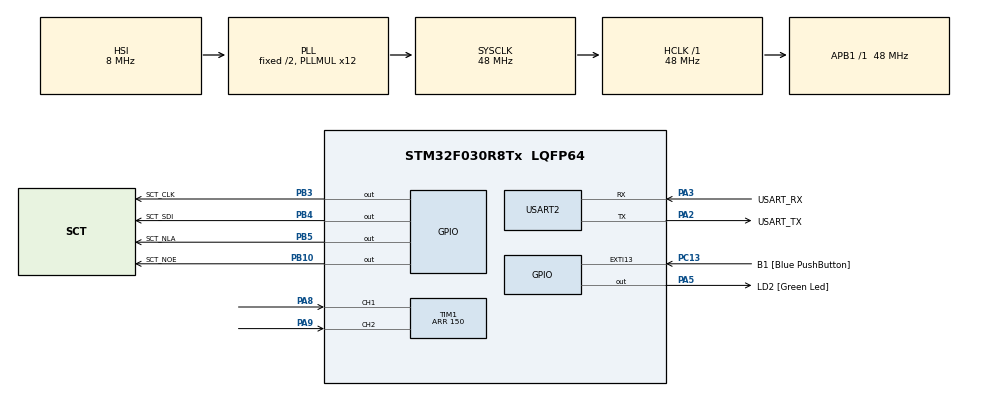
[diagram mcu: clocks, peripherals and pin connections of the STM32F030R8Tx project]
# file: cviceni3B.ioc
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Mcu.Family=STM32F0
Mcu.Name=STM32F030R8Tx
Mcu.Package=LQFP64
PA13.GPIO_Label=TMS
PA13.Mode=Serial_Wire
PA13.Signal=SYS_SWDIO
PA14.GPIO_Label=TCK
PA14.Mode=Serial_Wire
PA14.Signal=SYS_SWCLK
PA2.GPIO_Label=USART_TX
PA2.GPIO_Mode=GPIO_MODE_AF_PP
PA2.GPIO_PuPd=GPIO_NOPULL
PA2.GPIO_Speed=GPIO_SPEED_FREQ_LOW
PA2.Mode=Asynchronous
PA2.Signal=USART2_TX
PA3.GPIO_Label=USART_RX
PA3.GPIO_Mode=GPIO_MODE_AF_PP
PA3.GPIO_PuPd=GPIO_NOPULL
PA3.GPIO_Speed=GPIO_SPEED_FREQ_LOW
PA3.Mode=Asynchronous
PA3.Signal=USART2_RX
PA5.GPIO_Label=LD2 [Green Led]
PA5.GPIO_Mode=GPIO_MODE_OUTPUT_PP
PA5.GPIO_PuPd=GPIO_NOPULL
PA5.GPIO_Speed=GPIO_SPEED_FREQ_LOW
PA5.Signal=GPIO_Output
PA8.Signal=S_TIM1_CH1
PA9.Signal=S_TIM1_CH2
PB10.GPIO_Label=SCT_NOE
PB10.Signal=GPIO_Output
PB3.GPIO_Label=SCT_CLK
PB3.Signal=GPIO_Output
PB4.GPIO_Label=SCT_SDI
PB4.Signal=GPIO_Output
PB5.GPIO_Label=SCT_NLA
PB5.Signal=GPIO_Output
PC13.GPIO_Label=B1 [Blue PushButton]
PC13.GPIO_ModeDefaultEXTI=GPIO_MODE_IT_FALLING
PC13.Signal=GPXTI13
PC14-OSC32_IN.Mode=LSE-External-Oscillator
PC14-OSC32_IN.Signal=RCC_OSC32_IN
PC15-OSC32_OUT.Mode=LSE-External-Oscillator
PC15-OSC32_OUT.Signal=RCC_OSC32_OUT
PF0-OSC_IN.Mode=HSE-External-Clock-Source
PF0-OSC_IN.Signal=RCC_OSC_IN
PF1-OSC_OUT.Signal=RCC_OSC_OUT
ProjectManager.HeapSize=0x200
ProjectManager.StackSize=0x400
ProjectManager.TargetToolchain=STM32CubeIDE
RCC.AHBFreq_Value=48000000
RCC.APB1Freq_Value=48000000
RCC.APB1TimFreq_Value=48000000
RCC.HCLKFreq_Value=48000000
RCC.PLLMUL=RCC_PLL_MUL12
RCC.SYSCLKFreq_VALUE=48000000
RCC.SYSCLKSource=RCC_SYSCLKSOURCE_PLLCLK
SH.S_TIM1_CH1.0=TIM1_CH1,Encoder_Interface
SH.S_TIM1_CH2.0=TIM1_CH2,Encoder_Interface
TIM1.IC1Polarity=TIM_ICPOLARITY_FALLING
TIM1.Period=150
USART2.VirtualMode-Asynchronous=VM_ASYNC
board=NUCLEO-F030R8

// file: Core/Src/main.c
/* USER CODE BEGIN Header */
/**
  ******************************************************************************
  * @file           : main.c
  * @brief          : Main program body
  ******************************************************************************
  * @attention
  *
  * <h2><center>&copy; Copyright (c) 2021 STMicroelectronics.
  * All rights reserved.</center></h2>
  *
  * This software component is licensed by ST under BSD 3-Clause license,
  * the "License"; You may not use this file except in compliance with the
  * License. You may obtain a copy of the License at:
  *                        opensource.org/licenses/BSD-3-Clause
  *
  ******************************************************************************
  */
/* USER CODE END Header */
#include "main.h"

/* USER CODE BEGIN Includes */

#include "sct.h"
/* USER CODE END Includes */

TIM_HandleTypeDef htim1;

UART_HandleTypeDef huart2;

void SystemClock_Config(void);
static void MX_GPIO_Init(void);
static void MX_USART2_UART_Init(void);
static void MX_TIM1_Init(void);
/* USER CODE BEGIN PFP */
void SystemClock_Config(void);
static void MX_GPIO_Init(void);
static void MX_USART2_UART_Init(void);
/* USER CODE END PFP */

int main(void)
{

  /* MCU Configuration--------------------------------------------------------*/

  /* Reset of all peripherals, Initializes the Flash interface and the Systick. */
  HAL_Init();

  /* Configure the system clock */
  SystemClock_Config();

  /* Initialize all configured peripherals */
  MX_GPIO_Init();
  MX_USART2_UART_Init();
  MX_TIM1_Init();
  /* USER CODE BEGIN 2 */

  sct_init();
  sct_led(0x7A5C36DE);
  HAL_Delay(1000);

  HAL_TIM_Encoder_Start(&htim1, htim1.Channel);

  /* USER CODE END 2 */

  /* Infinite loop */
  while (1)
  {

	  /* USER CODE BEGIN 3 */

	  sct_value(__HAL_TIM_GET_COUNTER(&htim1));
	  HAL_Delay(50);

  }
  /* USER CODE END 3 */
}

void SystemClock_Config(void)
{
  RCC_OscInitTypeDef RCC_OscInitStruct = {0};
  RCC_ClkInitTypeDef RCC_ClkInitStruct = {0};

  /** Initializes the RCC Oscillators according to the specified parameters
  * in the RCC_OscInitTypeDef structure.
  */
  RCC_OscInitStruct.OscillatorType = RCC_OSCILLATORTYPE_HSI;
  RCC_OscInitStruct.HSIState = RCC_HSI_ON;
  RCC_OscInitStruct.HSICalibrationValue = RCC_HSICALIBRATION_DEFAULT;
  RCC_OscInitStruct.PLL.PLLState = RCC_PLL_ON;
  RCC_OscInitStruct.PLL.PLLSource = RCC_PLLSOURCE_HSI;
  RCC_OscInitStruct.PLL.PLLMUL = RCC_PLL_MUL12;
  RCC_OscInitStruct.PLL.PREDIV = RCC_PREDIV_DIV1;
  if (HAL_RCC_OscConfig(&RCC_OscInitStruct) != HAL_OK)
  {
    Error_Handler();
  }
  /** Initializes the CPU, AHB and APB buses clocks
  */
  RCC_ClkInitStruct.ClockType = RCC_CLOCKTYPE_HCLK|RCC_CLOCKTYPE_SYSCLK
                              |RCC_CLOCKTYPE_PCLK1;
  RCC_ClkInitStruct.SYSCLKSource = RCC_SYSCLKSOURCE_PLLCLK;
  RCC_ClkInitStruct.AHBCLKDivider = RCC_SYSCLK_DIV1;
  RCC_ClkInitStruct.APB1CLKDivider = RCC_HCLK_DIV1;

  if (HAL_RCC_ClockConfig(&RCC_ClkInitStruct, FLASH_LATENCY_1) != HAL_OK)
  {
    Error_Handler();
  }
}

static void MX_TIM1_Init(void)
{

  TIM_Encoder_InitTypeDef sConfig = {0};
  TIM_MasterConfigTypeDef sMasterConfig = {0};

  htim1.Instance = TIM1;
  htim1.Init.Prescaler = 0;
  htim1.Init.CounterMode = TIM_COUNTERMODE_UP;
  htim1.Init.Period = 150;
  htim1.Init.ClockDivision = TIM_CLOCKDIVISION_DIV1;
  htim1.Init.RepetitionCounter = 0;
  htim1.Init.AutoReloadPreload = TIM_AUTORELOAD_PRELOAD_DISABLE;
  sConfig.EncoderMode = TIM_ENCODERMODE_TI1;
  sConfig.IC1Polarity = TIM_ICPOLARITY_FALLING;
  sConfig.IC1Selection = TIM_ICSELECTION_DIRECTTI;
  sConfig.IC1Prescaler = TIM_ICPSC_DIV1;
  sConfig.IC1Filter = 0;
  sConfig.IC2Polarity = TIM_ICPOLARITY_RISING;
  sConfig.IC2Selection = TIM_ICSELECTION_DIRECTTI;
  sConfig.IC2Prescaler = TIM_ICPSC_DIV1;
  sConfig.IC2Filter = 0;
  if (HAL_TIM_Encoder_Init(&htim1, &sConfig) != HAL_OK)
  {
    Error_Handler();
  }
  sMasterConfig.MasterOutputTrigger = TIM_TRGO_RESET;
  sMasterConfig.MasterSlaveMode = TIM_MASTERSLAVEMODE_DISABLE;
  if (HAL_TIMEx_MasterConfigSynchronization(&htim1, &sMasterConfig) != HAL_OK)
  {
    Error_Handler();
  }

}

static void MX_USART2_UART_Init(void)
{

  huart2.Instance = USART2;
  huart2.Init.BaudRate = 38400;
  huart2.Init.WordLength = UART_WORDLENGTH_8B;
  huart2.Init.StopBits = UART_STOPBITS_1;
  huart2.Init.Parity = UART_PARITY_NONE;
  huart2.Init.Mode = UART_MODE_TX_RX;
  huart2.Init.HwFlowCtl = UART_HWCONTROL_NONE;
  huart2.Init.OverSampling = UART_OVERSAMPLING_16;
  huart2.Init.OneBitSampling = UART_ONE_BIT_SAMPLE_DISABLE;
  huart2.AdvancedInit.AdvFeatureInit = UART_ADVFEATURE_NO_INIT;
  if (HAL_UART_Init(&huart2) != HAL_OK)
  {
    Error_Handler();
  }

}

static void MX_GPIO_Init(void)
{
  GPIO_InitTypeDef GPIO_InitStruct = {0};

  /* GPIO Ports Clock Enable */
  __HAL_RCC_GPIOC_CLK_ENABLE();
  __HAL_RCC_GPIOF_CLK_ENABLE();
  __HAL_RCC_GPIOA_CLK_ENABLE();
  __HAL_RCC_GPIOB_CLK_ENABLE();

  /*Configure GPIO pin Output Level */
  HAL_GPIO_WritePin(LD2_GPIO_Port, LD2_Pin, GPIO_PIN_RESET);

  /*Configure GPIO pin Output Level */
  HAL_GPIO_WritePin(GPIOB, SCT_NOE_Pin|SCT_CLK_Pin|SCT_SDI_Pin|SCT_NLA_Pin, GPIO_PIN_RESET);

  /*Configure GPIO pin : B1_Pin */
  GPIO_InitStruct.Pin = B1_Pin;
  GPIO_InitStruct.Mode = GPIO_MODE_IT_FALLING;
  GPIO_InitStruct.Pull = GPIO_NOPULL;
  HAL_GPIO_Init(B1_GPIO_Port, &GPIO_InitStruct);

  /*Configure GPIO pin : LD2_Pin */
  GPIO_InitStruct.Pin = LD2_Pin;
  GPIO_InitStruct.Mode = GPIO_MODE_OUTPUT_PP;
  GPIO_InitStruct.Pull = GPIO_NOPULL;
  GPIO_InitStruct.Speed = GPIO_SPEED_FREQ_LOW;
  HAL_GPIO_Init(LD2_GPIO_Port, &GPIO_InitStruct);

  /*Configure GPIO pins : SCT_NOE_Pin SCT_CLK_Pin SCT_SDI_Pin SCT_NLA_Pin */
  GPIO_InitStruct.Pin = SCT_NOE_Pin|SCT_CLK_Pin|SCT_SDI_Pin|SCT_NLA_Pin;
  GPIO_InitStruct.Mode = GPIO_MODE_OUTPUT_PP;
  GPIO_InitStruct.Pull = GPIO_NOPULL;
  GPIO_InitStruct.Speed = GPIO_SPEED_FREQ_LOW;
  HAL_GPIO_Init(GPIOB, &GPIO_InitStruct);

}

void Error_Handler(void)
{
  __disable_irq();
  while (1)
  {
  }
}

/************************ (C) COPYRIGHT STMicroelectronics *****END OF FILE****/
